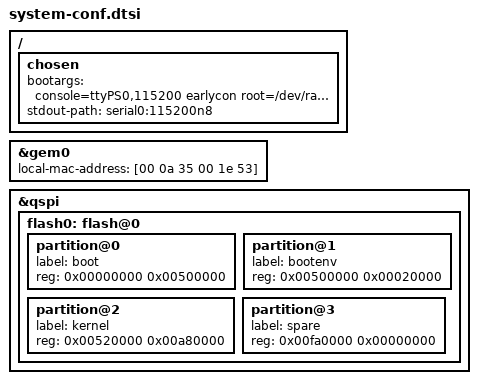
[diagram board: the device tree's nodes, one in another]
/*
 * CAUTION: This file is automatically generated by PetaLinux SDK.
 * DO NOT modify this file
 */


/ {
	chosen {
		bootargs = "console=ttyPS0,115200 earlycon root=/dev/ram0 rw";
		stdout-path = "serial0:115200n8";
	};
};

&gem0 {
	local-mac-address = [00 0a 35 00 1e 53];
};

&qspi {
	#address-cells = <1>;
	#size-cells = <0>;
	flash0: flash@0 {
		/delete-node/ partition@0;
		/delete-node/ partition@100000;
		/delete-node/ partition@600000;
		/delete-node/ partition@620000;
		partition@0 {
			label = "boot";
			reg = <0x00000000 0x00500000>;
		};
		partition@1 {
			label = "bootenv";
			reg = <0x00500000 0x00020000>;
		};
		partition@2 {
			label = "kernel";
			reg = <0x00520000 0x00a80000>;
		};
		partition@3 {
			label = "spare";
			reg = <0x00fa0000 0x00000000>;
		};
	};
};

